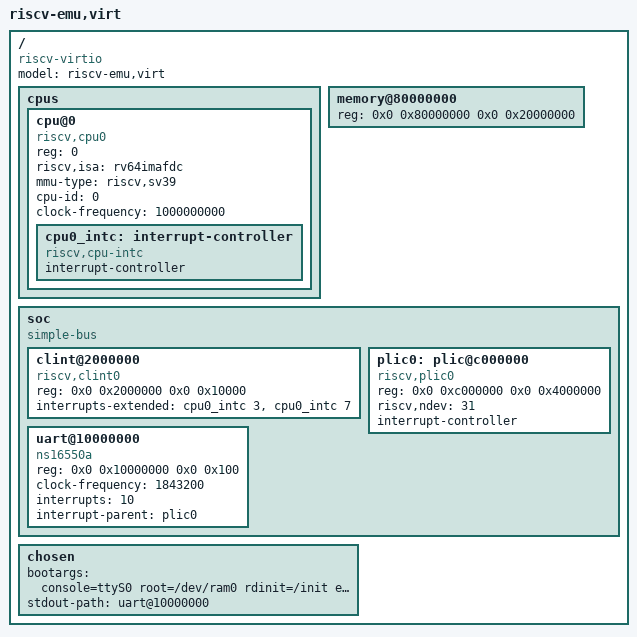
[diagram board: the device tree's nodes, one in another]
/dts-v1/;

/ {
    #address-cells = <2>;
    #size-cells = <2>;
    compatible = "riscv-virtio", "riscv";
    model = "riscv-emu,virt";

    cpus {
        #address-cells = <1>;
        #size-cells = <0>;

        cpu@0 {
            reg = <0>; // Hart ID 0
            compatible = "riscv,cpu0", "riscv";
            riscv,isa = "rv64imafdc";
            mmu-type = "riscv,sv39";
            cpu-id = <0>;
            clock-frequency = <1000000000>; // 1 GHz, just arbitary
            status = "okay"; // cpu enabled
            
            cpu0_intc: interrupt-controller {
                compatible = "riscv,cpu-intc";
                interrupt-controller;
                #interrupt-cells = <1>;
            };
        };
    };

    memory@80000000 {
        device_type = "memory";
        reg = <0x0 0x80000000 0x0 0x20000000>; // 512MB RAM
    };

    soc {
        #address-cells = <2>;
        #size-cells = <2>;
        compatible = "simple-bus";
        ranges;

        clint@2000000 {
            compatible = "riscv,clint0";
            reg = <0x0 0x2000000 0x0 0x10000>;
            interrupts-extended = <&cpu0_intc 3 &cpu0_intc 7>; // Machine software and timer interrupts (look at trap.h) 
        };

        plic0: plic@c000000 {
            compatible = "riscv,plic0";
            reg = <0x0 0xc000000 0x0 0x4000000>;
            riscv,ndev = <31>; // Max external interrupts PLIC can handle
            interrupt-controller;
            #interrupt-cells = <1>;
            // interrupt-parent = <&cpu0_intc>;
        };

        uart@10000000 {
            compatible = "ns16550a";
            reg = <0x0 0x10000000 0x0 0x100>;
            clock-frequency = <1843200>; // Clock frequency for ns16550a
            interrupts = <10>;
            interrupt-parent = <&plic0>;
        };
    };

    chosen {
        bootargs = "console=ttyS0 root=/dev/ram0 rdinit=/init earlycon"; // Live boot command line
        stdout-path = "uart@10000000"; // Specifies which device is the console
    };
};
